# PCIE1_CORE_DBN_CFG_PCIE_CORE register map
Vendor: Texas Instruments
Registers are 32-bit, read-write, reset 0x0 unless marked. A register's access mark holds for its fields unless they carry their own. Offsets are as the file gives them; [hi:lo] are bit positions.

## PCIE1_CORE_DBN_CFG_PCIE_CORE (part 3 of 7)
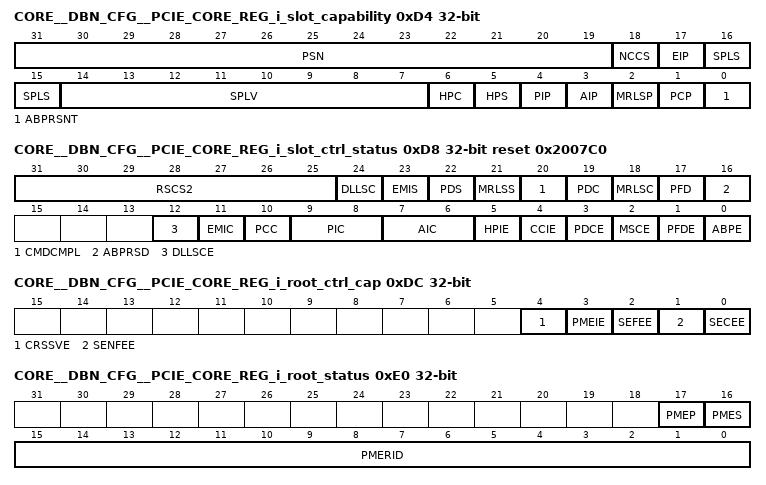
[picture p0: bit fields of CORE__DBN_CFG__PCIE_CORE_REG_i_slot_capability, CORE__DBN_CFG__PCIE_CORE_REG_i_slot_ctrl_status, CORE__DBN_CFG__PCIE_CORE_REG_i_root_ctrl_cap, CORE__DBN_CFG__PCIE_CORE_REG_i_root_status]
0xD4 CORE__DBN_CFG__PCIE_CORE_REG_i_slot_capability ro — The Slot Capabilities register identifies PCI Express slot specific capabilities.
  [31:19] PSN — This field indicates the physical slot number attached to this Port. This field must be hardware initialized to a value that assigns a slot number that is unique within the chassis, regardless of the form factor associated with the slot. This field must be initialized to zero for Ports connected to devices that are either integrated on the system board or integrated within the same silicon as the Switch device or Root Port.
  [18] NCCS — When Set, this bit indicates that this slot does not generate software notification when an issued command is completed by the Hot-Plug Controller. This bit is only permitted to be Set if the hot-plug capable Port is able to accept writes to all fields of the Slot Control register without delay between successive writes.
  [17] EIP — When Set, this bit indicates that an Electromechanical Interlock is implemented on the chassis for this slot.
  [16:15] SPLS — Specifies the scale used for the Slot Power Limit Value . Range of Values: 00b = 1.0x 01b = 0.1x 10b = 0.01x 11b = 0.001x This register must be implemented if the Slot Implemented bit is Set. Writes to this register also cause the Port to send the Set_Slot_Power_Limit Message. The default value prior to hardware/firmware initialization is 00b.
  [14:7] SPLV — In combination with the Slot Power Limit Scale value, specifies the upper limit on power supplied by the slot [see Section 6.9] or by other means to the adapter. Power limit [in Watts] is calculated by multiplying the value in this field by the value in the Slot Power Limit Scale field except when the Slot Power Limit Scale field equals 00b [1.0x] and Slot Power Limit Value exceeds EFh, the following alternative encodings are used: F0h = 250 W Slot Power Limit F1h = 275 W Slot Power Limit F2h = 300 W Slot Power Limit F3h to FFh = Reserved for Slot Power Limit values above 300 W This register must be implemented if the Slot Implemented bit is Set. Writes to this register also cause the Port to send the Set_Slot_Power_Limit Message. The default value prior to hardware/firmware initialization is 0000 0000b.
  [6] HPC — When Set, this bit indicates that this slot is capable of supporting hot-plug operations.
  [5] HPS — When Set, this bit indicates that an adapter present in this slot might be removed from the system without any prior notification. This is a form factor specific capability. This bit is an indication to the operating system to allow for such removal without impacting continued software operation.
  [4] PIP — When Set, this bit indicates that a Power Indicator is electrically controlled by the chassis for this slot.
  [3] AIP — When Set, this bit indicates that an Attention Indicator is electrically controlled by the chassis.
  [2] MRLSP — When Set, this bit indicates that an MRL Sensor is implemented on the chassis for this slot.
  [1] PCP — When Set, this bit indicates that a software programmable Power Controller is implemented for this slot/adapter [depending on form factor].
  [0] ABPRSNT — When Set, this bit indicates that an Attention Button for this slot is electrically controlled by the chassis.
0xD8 CORE__DBN_CFG__PCIE_CORE_REG_i_slot_ctrl_status access not given reset 0x2007C0 — This register contains control bits specific to PCI Express slot parameters and status bits specific to the PCI Express Slot. All the read-write bits in this register can also be written from the local management APB bus.
  [31:25] RSCS2 ro
  [24] DLLSC — This bit is Set when the value reported in the Data Link Layer Link Active bit of the Link Status register is changed. In response to a Data Link Layer State Changed event, software must read the Data Link Layer Link Active bit of the Link Status register to determine if the Link is active before initiating configuration cycles to the hot plugged device. (access R/W1TC)
  [23] EMIS ro — If an Electromechanical Interlock is implemented, this bit indicates the status of the Electromechanical Interlock. Defined encodings are: 0b Electromechanical Interlock Disengaged 1b Electromechanical Interlock Engaged
  [22] PDS ro — This bit indicates the presence of an adapter in the slot, reflected by the logical 'OR' of the Physical Layer in-band presence detect mechanism and, if present, any out-of-band presence detect mechanism defined for the slot's corresponding form factor. Note that the in-band presence detect mechanism requires that power be applied to an adapter for its presence to be detected. Consequently, form factors that require a power controller for hot-plug must implement a physical pin presence detect mechanism. Defined encodings are: 0b Slot Empty 1b Card Present in slot.
  [21] MRLSS ro — This bit reports the status of the MRL sensor if implemented. Defined encodings are: 0b MRL Closed 1b MRL Open
  [20] CMDCMPL — If Command Completed notification is supported [if the No Command Completed Support bit in the Slot Capabilities register is 0b], this bit is Set when a hot-plug command has completed and the Hot-Plug Controller is ready to accept a subsequent command. The Command Completed status bit is Set as an indication to host software that the Hot- Plug Controller has processed the previous command and is ready to receive the next command; it provides no guarantee that the action corresponding to the command is complete. If Command Completed notification is not supported, this bit must be hardwired to 0b. (access R/W1TC)
  [19] PDC — This bit is set when the value reported in the Presence Detect State bit is changed. (access R/W1TC)
  [18] MRLSC — If an MRL sensor is implemented, this bit is Set when a MRL Sensor state change is detected. If an MRL sensor is not implemented, this bit must not be Set. (access R/W1TC)
  [17] PFD — If a Power Controller that supports power fault detection is implemented, this bit is Set when the Power Controller detects a power fault at this slot. Note that, depending on hardware capability, it is possible that a power fault can be detected at any time, independent of the Power Controller Control setting or the occupancy of the slot. If power fault detection is not supported, this bit must not be Set. (access R/W1TC)
  [16] ABPRSD — If an Attention Button is implemented, this bit is Set when the attention button is pressed. If an Attention Button is not supported, this bit must not be Set. (access R/W1TC)
  [12] DLLSCE rw — If the Data Link Layer Link Active Reporting capability is 1b, this bit enables software notification when Data Link Layer Link Active bit is changed. If the Data Link Layer Link Active Reporting Capable bit is 0b, this bit is permitted to be read-only with a value of 0b. Default value of this bit is 0b.
  [11] EMIC ro — If an Electromechanical Interlock is implemented, a write of 1b to this bit causes the state of the interlock to toggle. A write of 0b to this bit has no effect. A read of this bit always returns a 0b.
  [10] PCC rw — If a Power Controller is implemented, this bit when written sets the power state of the slot per the defined encodings. Reads of this bit must reflect the value from the latest write, even if the corresponding hot-plug command is not complete, unless software issues a write, if required to, without waiting for the previous command to complete in which case the read value is undefined. The defined encodings are: 0b Power On 1b Power Off
  [9:8] PIC rw — If a Power Indicator is implemented, writes to this field set the Power Indicator to the written state. Reads of this field must reflect the value from the latest write,Defined encodings are: 00b Reserved 01b On 10b Blink 11b Off
  [7:6] AIC rw — If an Attention Indicator is implemented, writes to this field set the Attention Indicator to the written state. Reads of this field must reflect the value from the latest write,Defined encodings are: 00b Reserved 01b On 10b Blink 11b Off
  [5] HPIE rw — When Set, this bit enables generation of an interrupt on enabled hot-plug events. If the Hot Plug Capable bit in the Slot Capabilities register is Clear, this bit is permitted to be read-only with a value of 0b. Default value of this bit is 0b.
  [4] CCIE rw — If Command Completed notification is supported [if the No Command Completed Support bit in the Slot Capabilities register is 0b], when Set, this bit enables software notification when a hot-plug command is completed by the Hot-Plug Controller. If Command Completed notification is not supported, this bit must be hardwired to 0b. Default value of this bit is 0b.
  [3] PDCE rw — When Set, this bit enables software notification on a presence detect changed event. If the Hot-Plug Capable bit in the Slot Capabilities register is 0b, this bit is permitted to be read-only with a value of 0b. Default value of this bit is 0b.
  [2] MSCE rw — When Set, this bit enables software notification on a MRL sensor changed event If the MRL Sensor Present bit in the Slot Capabilities register is Clear, this bit is permitted to be read-only with a value of 0b. Default value of this bit is 0b.
  [1] PFDE rw — When Set, this bit enables software notification on a power fault event If a Power Controller that supports power fault detection is not implemented, this bit is permitted to be read-only with a value of 0b. Default value of this bit is 0b.
  [0] ABPE rw — When Set to 1b, this bit enables software notification on an attention button pressed event. If the Attention Button Present bit in the Slot Capabilities register is 0b, this bit is permitted to be read-only with a value of 0b. Default value of this bit is 0b.
0xDC CORE__DBN_CFG__PCIE_CORE_REG_i_root_ctrl_cap access per field — This register controls and identifies PCI Express Root Complex specific parameters.
  [4] CRSSVE ro — This capability is not implemented and this bit is hardwired to 0b.
  [3] PMEIE rw — This field can be read and written from the local management APB bus, but its value is not used within the Controller.
  [2] SEFEE rw — This field can be read and written from the local management APB bus, but its value is not used within the Controller.
  [1] SENFEE rw — This field can be read and written from the local management APB bus, but its value is not used within the Controller.
  [0] SECEE rw — This field can be read and written from the local management APB bus, but its value is not used within the Controller.
0xE0 CORE__DBN_CFG__PCIE_CORE_REG_i_root_status access not given — This register controls and identifies PCI Express Root Complex specific parameters.
  [17] PMEP ro — This field can be written from the APB bus by setting [21] bit high of the pcie_mgmt_APB_ADDR during a local management register write.
  [16] PMES — This field is not set by the Controller but can be cleared by writing a 1 from the local management APB bus. This field can be written from the APB bus by setting [21] bit high of the pcie_mgmt_APB_ADDR during a local management register write. (access R/W1TC)
  [15:0] PMERID ro — This field can be written from the APB bus by setting [21] bit high of the pcie_mgmt_APB_ADDR during a local management register write.
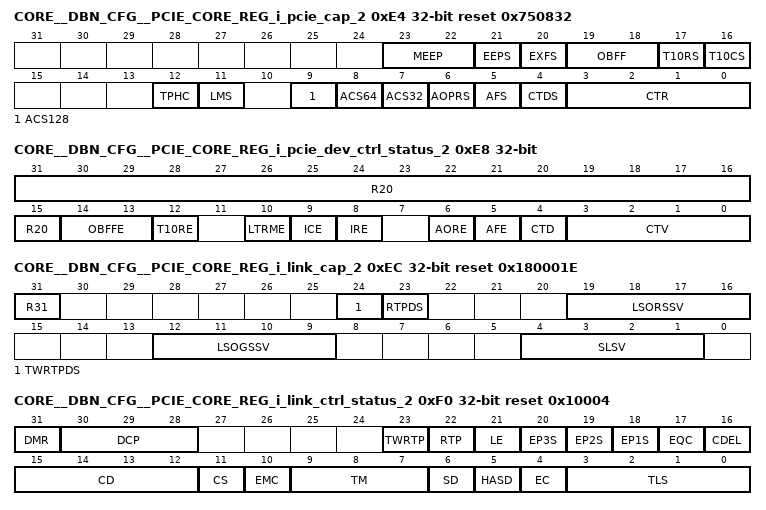
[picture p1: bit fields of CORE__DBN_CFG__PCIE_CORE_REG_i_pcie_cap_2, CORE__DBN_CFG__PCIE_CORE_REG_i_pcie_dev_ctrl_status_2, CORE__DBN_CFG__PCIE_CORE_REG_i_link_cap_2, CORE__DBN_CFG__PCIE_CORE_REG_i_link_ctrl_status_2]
0xE4 CORE__DBN_CFG__PCIE_CORE_REG_i_pcie_cap_2 ro reset 0x750832 — This register advertises the capabilities of the PCI Express device.
  [23:22] MEEP — Indicates the maximum number of End-End TLP Prefixes supported by the Function. The supported values are: 01b 1 End-End TLP Prefix 10b 2 End-End TLP Prefixes. This field can be written from the APB bus by setting [21] bit high of the pcie_mgmt_APB_ADDR during a local management register write
  [21] EEPS — Indicates whether the Function supports End-End TLP Prefixes. A 1 in this field indicates that the Function supports receiving TLPs containing End-End TLP Prefixes. This field can be written from the APB bus by setting [21] bit high of the pcie_mgmt_APB_ADDR during a local management register write
  [20] EXFS — Indicates that the Function supports the 3-bit definition of the Fmt field in the TLP header. This bit is hardwired to 1 for all Physical Functions.
  [19:18] OBFF — A 1 in this bit position indicates that the Function supports the Optimized Buffer Flush/Fill [OBFF] capability using message signaling. This field can be written from the APB bus by setting [21] bit high of the pcie_mgmt_APB_ADDR during a local management register write
  [17] T10RS — If set function supports 1-bit requester capability; otherwise, the function does not. This bit can be disabled using local management register.
  [16] T10CS — If set function supports 1-bit completer capability; otherwise, the function does not. This field can be modified using local management interface.
  [12] TPHC — Hardwired to 0.
  [11] LMS — A value of 1b indicates support for the optional Latency Tolerance Reporting [LTR] mechanism. This field can be written from the APB bus by setting [21] bit high of the pcie_mgmt_APB_ADDR during a local management register write.
  [9] ACS128 — Hardwired to 0.
  [8] ACS64 — Hardwired to 0.
  [7] ACS32 — Hardwired to 0.
  [6] AOPRS — Applicable only to Switch Upstream Ports, Switch Downstream Ports, and Root Ports; must be 0b for other Function types. This bit must be set to 1b if the Port supports this optional capability. This field can be written from the APB bus by setting [21] bit high of the pcie_mgmt_APB_ADDR during a local management register write.
  [5] AFS — A 1 in this bit indicates that the device is able to forward TLPs with function number greater than 8. This field can be written from the APB bus by setting [21] bit high of the pcie_mgmt_APB_ADDR during a local management register write.
  [4] CTDS — A 1 in this field indicates that the associated Function supports the capability to turn off its Completion timeout. This field can be written from the APB bus by setting [21] bit high of the pcie_mgmt_APB_ADDR during a local management register write.
  [3:0] CTR — Specifies the Completion Timeout values supported by the device. This field is set by default to 0010 [10 ms - 250 ms], but can be modified from the local management APB bus. The actual timeout values are in two programmable local management registers, which allow the timeout settings of the two sub-ranges within Range B to be programmed independently. This field can be written from the APB bus by setting [21] bit high of the pcie_mgmt_APB_ADDR during a local management register write.
0xE8 CORE__DBN_CFG__PCIE_CORE_REG_i_pcie_dev_ctrl_status_2 access per field — This register contains control and status bits associated with the device.
  [31:15] R20 ro
  [14:13] OBFFE rw — Enables the Optimized Buffer Flush/Fill [OBFF] capability in the device. Valid settings are 00 [disabled], 01 [Variation A], and 10 [Variation B].
  [12] T10RE ro — 10bit TAGs generation are not supported in this configuration.
  [10] LTRME rw — This must be set to 1 to enable the Latency Tolerance Reporting Mechanism. This bit is implemented only in PF 0. Its default value is 1, but can be modified from the local management bus. This bit is read-only in PF 1.
  [9] ICE rw — When this bit is 1, the RC is allowed to set the ID-based Ordering [IDO] Attribute bit in the Completions it generates.
  [8] IRE rw — When this bit is 1, the RC is allowed to set the ID-based Ordering [IDO] Attribute bit in the requests it generates.
  [6] AORE ro — This bit must be set to enable the generation of Atomic Op Requests. If the client logic attempts to send an Atomic Op when this bit is not set, logic in the Controller will nullify the TLP on its way to the link.
  [5] AFE rw — A 1 in this filed indicates that the port treats fields 7:0 of the ID as function number while converting a Type 1 config packet to type 0 config packet.
  [4] CTD rw — Setting this bit disables the Completion Timeout in the device.
  [3:0] CTV rw — Specifies the Completion Timeout value for the device. Allowable values are 0101 [sub-range 1] and 0110 [sub-range 2]. The corresponding timeout values are stored in the local management register's Completion Timeout Interval Registers 0 and 1, respectively. Value of 0 selects completion timeout from Completion-Timeout-Interval-Registers-0 in local management register.
0xEC CORE__DBN_CFG__PCIE_CORE_REG_i_link_cap_2 ro reset 0x180001E — This register advertises the supported link speeds of the Controller.
  [31] R31 — Indicates support for the optional Device Readiness Status [DRS] capability. This capability is currently not supported in the Controller.
  [24] TWRTPDS — When set to 1b, this bit indicates that the associated Port supports detection and reporting of two Retimers presence. This bit is valid for both Downstream Ports and Upstream Ports.
  [23] RTPDS — When set to 1b, this bit indicates that the associated Port supports detection and reporting of Retimer presence. This bit is valid for both Downstream Ports and Upstream Ports.
  [19:16] LSORSSV — If this field is non-zero, it indicates that the Port, when operating at the indicated speed[s] supports SRIS and also supports receiving SKP OS at the rate defined for SRNS while running in SRIS.
  [12:9] LSOGSSV — If this field is non-zero, it indicates that the Port, when operating at the indicated speed[s] supports SRIS and also supports software control of the SKP Ordered Set transmission scheduling rate.
  [4:1] SLSV — This field indicates the supported link speeds of the Controller. For each bit, a value of 1 indicates that the corresponding link speed is supported, while a value of 0 indicates that the corresponding speed is not supported. The bits corresponding to various link speeds are: Bit 1 = Link Speed 2.5 GT/s, Bit 2 = Link Speed 5 GT/s, Bit 3 = Link Speed 8 GT/s, Bit 4 = Link Speed 16 GT/s. This field is hardwired to 0001 [2.5 GT/s] when the PCIE_GENERATION_SEL strap pins of the Controller are set to 0, 0011 [2.5 and 5 GT/s] when the strap is set to 1, and 0111 [2.5, 5, and 8 GT/s] when the strap pin is set to 10, and 1111 [2.5, 5, 8 and 16 GT/s] when the strap pin is set to 11.
0xF0 CORE__DBN_CFG__PCIE_CORE_REG_i_link_ctrl_status_2 access not given reset 0x10004 — This register contains control and status bits specific to the PCI Express link.
  [31] DMR ro — DRS is not supported by the Controller and hence this field is not implemented.
  [30:28] DCP ro — DRS is not supported by the Controller and hence this field is not implemented.
  [23] TWRTP ro — When set to 1b, this bit indicates that two Retimers were present during the most recent Link negotiation.
  [22] RTP ro — When set to 1b, this bit indicates that a Retimer was present during the most recent Link negotiation.
  [21] LE — When the Controller [RP] receives an 8GTs equalization request from an Upstream Port the Controller internally sets this bit to 1. [i.e. when RP is in the Recovery.RcvrCfg state and receives 8 consecutive TS2 Ordered Sets with the Request Equalization bit set to 1b] The LOCAL_INTERRUPT output is also asserted if Link Equalization Request Interrupt Enable is enabled. (access R/W1TC)
  [20] EP3S ro — This bit, when set to 1, indicates that the Phase 3 of the Transmitter Equalization procedure has completed successfully. STICKY
  [19] EP2S ro — This bit, when set to 1, indicates that the Phase 2 of the Transmitter Equalization procedure has completed successfully. STICKY
  [18] EP1S ro — This bit, when set to 1, indicates that the Phase 1 of the Transmitter Equalization procedure has completed successfully. STICKY
  [17] EQC ro — This bit, when set to 1, indicates that the Transmitter Equalization procedure has completed. STICKY
  [16] CDEL ro — This status bit indicates the current operating de-emphasis level of the transmitter [0 = -6dB, 1 = -3.5dB].
  [15:12] CD rw — This bit sets the de-emphasis level [for 5 GT/s operation] or the Transmitter Preset level [for 8 GT/s or 16 GT/s operation] when the LTSSM enters the Polling.Compliance state because of software setting the Enter Compliance bit in this register. It is used only when the link is running at 5 GT/s or 8 GT/s or 16 GT/s. At 5 GT/s, the only valid setting are 0 [-6 dB] and 1 [-3.5 dB]. STICKY
  [11] CS rw — When this bit is set to 1, the device will transmit SKP ordered sets between compliance patterns. STICKY
  [10] EMC rw — This field is intended for debug and compliance testing purposes only. If this bit is set to 1, the device will transmit the Modified Compliance Pattern when the LTSSM enters the Polling.Compliance substate. STICKY
  [9:7] TM rw — This field is intended for debug and compliance testing purposes only. It controls the non-deemphasized voltage level at the transmitter outputs. Its encodings are: 000 = Normal operating range, 001 = 800 - 1200 mV for full swing and 400 - 700 mV for half swing, 010 - 111 = See PCI Express Base Specification 2.0. This field is reset to 0 when th LTSSM enters the Polling.Configuration substate during link training. STICKY.
  [6] SD rw — This bit selects the de-emphasis level when the Controller is operating at 5 GT/s [0 = -6 dB, 1 = -3.5 dB].
  [5] HASD rw — When this bit is set, the LTSSM is prevented from changing the operating speed of the link, other than reducing the speed to correct unreliable operation of the link. STICKY
  [4] EC rw — This bit is used to force the Endpoint device to enter the Compliance mode. Software sets this bit to 1 and initiates a hot reset to force the device into the Compliance mode. The target speed for the Compliance mode is determined by the Target Link Speed field of this register. STICKY.
  [3:0] TLS rw — This field sets the target speed when the software forces the link into Compliance mode by setting the Enter Compliance bit in this register [0001 = 2.5 GT/s, 0010 = 5 GT/s, 0100 = 8 GT/s,1000 = 16 GT/s]. The default value of this field is 0001 [2.5 GT/s] when the PCIE_GENERATION_SEL[1:0] strap pins of the Controller are set to 0, 0010 [5 GT/s] when the strap is set to 1, and 0011 [8 GT/s] when the strap pin is set to 10 , and 0100 [16 GT/s] when the strap pin is set to 11. STICKY.
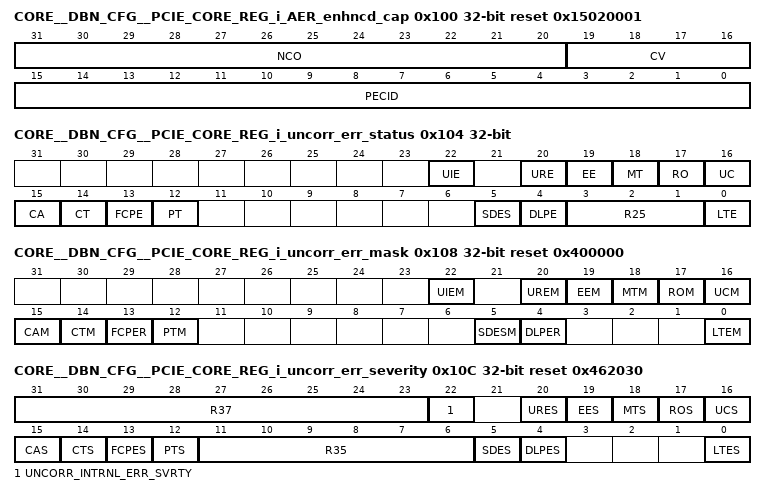
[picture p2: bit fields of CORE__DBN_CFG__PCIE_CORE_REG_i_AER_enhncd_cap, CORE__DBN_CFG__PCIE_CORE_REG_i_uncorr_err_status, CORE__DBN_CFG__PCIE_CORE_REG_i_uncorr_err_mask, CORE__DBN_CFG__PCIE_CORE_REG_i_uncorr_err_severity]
0x100 CORE__DBN_CFG__PCIE_CORE_REG_i_AER_enhncd_cap ro reset 0x15020001 — This is the first register in the PCI Express Advanced Error Reporting Capability Structure. This register contains the PCI Express Extended Capability ID, the capability version , and the pointer to the next capability structure.
  [31:20] NCO — Indicates offset to the next PCI Express capability structure. The default next pointer value is dynamic and is dependent on whether the strap or LMI bits are set.
  [19:16] CV — Specifies the SIG assigned value for the version of the capability structure. This field is set by default to 4'h2.
  [15:0] PECID — This field is hardwired to the Capability ID assigned by PCI SIG to the PCI Express AER Extended Capability Structure [0001 hex].
0x104 CORE__DBN_CFG__PCIE_CORE_REG_i_uncorr_err_status access not given — This register provides the status of the various uncorrectable errors detected by the PCI Express Controller. Software may clear any error bit by writing a 1 into the corresponding bit position. The states of the bits in the Uncorrectable Error Mask Register have no effect on the status bits of this register. In the case of certain errors detected by the Transaction Layer, the associated TLP header is logged in the Header Log Registers.
  [22] UIE — This bit is set when the Controller has detected an internal uncorrectable error [HAL parity error or an uncorrectable ECC error while reading from any of the RAMs]. This bit is also set in response to the client signaling an internal error through the input UNCORRECTABLE_ERROR_IN. This error is considered fatal by default. (access R/W1TC)
  [20] URE — This bit is set when the Controller has received a request from the link that it does not support. This error is not Function-specific. This error is considered non-fatal by default, except for the special case outlined in PCI Express Base Specification 2.0. The header of the received request that caused the error is logged in the Header Log Registers. (access R/W1TC)
  [19] EE — This bit is set when the Controller has detected an ECRC error in a received TLP. (access R/W1TC)
  [18] MT — This bit is set when the Controller receives a malformed TLP from the link. This error is considered fatal by default. The header of the received TLP with error is logged in the Header Log Registers. (access R/W1TC)
  [17] RO — This bit is set when the Controller receives a TLP in violation of the receive credit currently available. (access R/W1TC)
  [16] UC — This bit is set when the Controller has received an unexpected Completion packet from the link. (access R/W1TC)
  [15] CA — This bit is set when the Controller has returned the Completer Abort [CA] status to a request received from the link. This error is considered non-fatal by default, except for the special cases outlined in PCI Express Base Specification 2.0. The header of the received request that caused the error is logged in the Header Log Registers. (access R/W1TC)
  [14] CT — This bit is set when the completion timer associated with an outstanding request times out. This error is considered non-fatal by default. (access R/W1TC)
  [13] FCPE — This bit is set when certain violations of the flow control protocol are detected by the Controller. (access R/W1TC)
  [12] PT — This bit is set when the Controller receives a poisoned TLP from the link. This error is considered non-fatal by default. The header of the received TLP with error is logged in the Header Log Registers. (access R/W1TC)
  [5] SDES — This error status indicates Link up to Link down event. So Status bit is set upon LINK_DOWN_RESET_OUT event. This field is applicable to RC only and not for EP as per PCIE-spec. (access R/W1TC)
  [4] DLPE — This bit is set when the Controller receives an Ack or Nak DLLP whose sequence does not correspond to that of an unacknowledged TLP or that of the last acknowledged TLP [for details, refer to the PCI Express Base Specifications]. (access R/W1TC)
  [3:1] R25 ro
  [0] LTE — This error indicates that link training is not successful and transition back to detect state. This Status bit is set on any LTSSM transition from Configuration to Detect or Recovery to Detect. This field is applicable to RC only and not for EP as per PCIE-spec. (access R/W1TC)
0x108 CORE__DBN_CFG__PCIE_CORE_REG_i_uncorr_err_mask reset 0x400000 — The mask bits in this register control the reporting of uncorrectable errors. For each error type in the Uncorrectable Error Status Register, there is a corresponding bit in this register to mask its reporting. Setting the mask bit has the following effects: (1) The occurrence of the error does not cause activation of the FATAL_ERROR_OUT or NON_FATAL_ERROR_OUT output of the Controller, depending on the severity of the error. (2) The header of the TLP in which the error was detected is not logged in the Header Log Registers. (3) The First Error Pointer in the Advanced Error Capabilities and Control Register is not updated on the detection of the error. The individual bits of the mask register are described below.
  [22] UIEM — This bit is set to mask the reporting of internal errors. STICKY.
  [20] UREM — This bit is set to mask the reporting of unexpected requests received from the link. STICKY.
  [19] EEM — This bit is set to mask the reporting of ECRC errors. STICKY.
  [18] MTM — This bit is set to mask the reporting of malformed TLPs received from the link. STICKY.
  [17] ROM — This bit is set to mask the reporting of violations of receive credit. STICKY.
  [16] UCM — This bit is set to mask the reporting of unexpected Completions received by the Controller. STICKY.
  [15] CAM — This bit is set to mask the reporting of the Controller sending a Completer Abort. STICKY.
  [14] CTM — This bit is set to mask the reporting of Completion Timeouts. STICKY.
  [13] FCPER — This bit is set to mask the reporting of Flow Control Protocol Errors. STICKY.
  [12] PTM — This bit is set to mask the reporting of a Poisoned TLP. STICKY.
  [5] SDESM — This bit is set to mask the reporting of Surprise Down Error Status Mask. STICKY. This field is applicable to RC only and not for EP as per PCIE-spec.
  [4] DLPER — This bit is set to mask the reporting of Data Link Protocol Errors. STICKY.
  [0] LTEM — This bit is set to mask the reporting of Link Training Error Mask. STICKY. This field is applicable to RC only and not for EP as per PCIE-spec.
0x10C CORE__DBN_CFG__PCIE_CORE_REG_i_uncorr_err_severity access per field reset 0x462030 — The setting of this register determines whether an uncorrectable error is reported as a fatal error or non-fatal, that is, whether the FATAL_ERROR_OUT or NON_FATAL_ERROR_OUT output of the Controller is activated. If a severity bit of this register is 0,the corresponding error is reported by the Controller by asserting NON_FATAL_ERROR_OUT. Otherwise, it is reported by asserting FATAL_ERROR_OUT.
  [31:23] R37 ro
  [22] UNCORR_INTRNL_ERR_SVRTY rw — Severity of internal errors [0 = Non-Fatal, 1 = Fatal].
  [20] URES rw — Severity of unexpected requests received from the link [0 = Non-Fatal, 1 = Fatal]. STICKY.
  [19] EES rw — Severity of ECRC errors [0 = Non-Fatal, 1 = Fatal]. STICKY.
  [18] MTS rw — Severity of malformed TLPs received from the link [0 = Non-Fatal, 1 = Fatal]. STICKY.
  [17] ROS rw — Severity of receive credit violations [0 = Non-Fatal, 1 = Fatal]. STICKY.
  [16] UCS rw — Severity of unexpected Completions received by the Controller [0 = Non-Fatal, 1 = Fatal]. STICKY.
  [15] CAS rw — Severity of sending a Completer Abort [0 = Non-Fatal, 1 = Fatal]. STICKY.
  [14] CTS rw — Severity of Completion Timeouts [0 = Non-Fatal, 1 = Fatal]. STICKY.
  [13] FCPES rw — Severity of a Flow Control Protocol Error [0 = Non-Fatal, 1 = Fatal]. STICKY.
  [12] PTS rw — Severity of a Poisoned TLP error [0 = Non-Fatal, 1 = Fatal]. STICKY.
  [11:6] R35 ro
  [5] SDES rw — surprise down error severity [0 = Non-Fatal, 1 = Fatal]. STICKY. This field is applicable to RC only and not for EP as per PCIE-spec.
  [4] DLPES rw — Severity of Data Link Protocol Errors [0 = Non-Fatal, 1 = Fatal]. STICKY.
  [0] LTES rw — Severity of Link Training Error [0 = Non-Fatal, 1 = Fatal]. STICKY. This field is applicable to RC only and not for EP as per PCIE-spec.
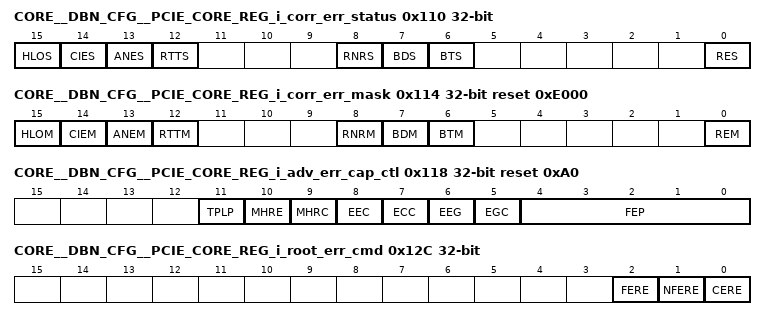
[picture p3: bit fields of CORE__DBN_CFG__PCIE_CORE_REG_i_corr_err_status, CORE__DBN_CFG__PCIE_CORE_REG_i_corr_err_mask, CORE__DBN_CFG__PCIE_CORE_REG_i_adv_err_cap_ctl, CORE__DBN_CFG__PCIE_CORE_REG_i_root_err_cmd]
0x110 CORE__DBN_CFG__PCIE_CORE_REG_i_corr_err_status access not given — This register provides the status of the various correctable errors detected by the PCI Express Controller. Software may clear any error bit by writing a 1 into the corresponding bit position. The states of the bits in the Correctable Error Mask Register have no effect on the status bits of this register. The setting of a correctable error status bit causes the Controller to assert the CORRECTABLE_ERROR_OUT output if the error is not masked in the Correctable Error Mask Register. Header logging of received TLPs does not apply to correctable errors.
  [15] HLOS — This bit is set on a Header Log Register overflow, that is, when the header could not be logged in the Header Log Register because it is occupied by a previous header. (access R/W1TC)
  [14] CIES — This bit is set when the Controller has detected an internal correctable error condition [a correctable ECC error while reading from any of the RAMs]. This bit is also set in response to the client signaling an internal error through the input CORRECTABLE_ERROR_IN. (access R/W1TC)
  [13] ANES — This bit is set when an uncorrectable error occurs, which is determined to belong to one of the special cases described in the PCI Express Base Specification 2.0. This causes the Controller to assert the CORRECTABLE_ERROR_OUT output in place of NON_FATAL_ERROR_OUT. (access R/W1TC)
  [12] RTTS — This bit is set when the replay timer in the Data Link Layer of the Controller times out, causing the Controller to re-transmit a TLP. (access R/W1TC)
  [8] RNRS — This bit is set when the replay count rolls over after three re-transmissions of a TLP at the Data Link Layer of the Controller. (access R/W1TC)
  [7] BDS — This bit is set when an LCRC error is detected in a received DLLP, and no errors were detected by the Physical Layer. (access R/W1TC)
  [6] BTS — This bit is set when an error is detected in a received TLP by the Data Link Layer of the Controller the conditions causing this error are [1] an LCRC error, [2] the packet terminates with EDB symbol, but its LCRC field does not equal the inverted value of the calculated CRC. (access R/W1TC)
  [0] RES — This bit is set when an error is detected in the receive side of the Physical Layer of the Controller [e.g. an 8b10b decode error]. (access R/W1TC)
0x114 CORE__DBN_CFG__PCIE_CORE_REG_i_corr_err_mask reset 0xE000 — The mask bits in this register control the reporting of correctable errors. For each error type in the Correctable Error Status Register, there is a corresponding bit in this register to mask its reporting. When a mask bit is set the occurrence of the error is not reported (by asserting the CORRECTABLE_ERROR_OUT output).
  [15] HLOM — This bit, when set, masks the reporting of an error in response to a Header Log register overflow. STICKY.
  [14] CIEM — This bit, when set, masks the reporting of an error in response to a corrected internal error condition. STICKY.
  [13] ANEM — This bit, when set, masks the reporting of an error in response to an uncorrectable error occurence, which is determined to belong to one of the special cases in the PCI Express Base Specification 2.0. STICKY.
  [12] RTTM — This bit, when set, masks the reporting of an error in response to a Replay Timer timeout event. STICKY.
  [8] RNRM — This bit, when set, masks the reporting of an error in response to a Replay Number Rollover event. STICKY.
  [7] BDM — This bit, when set, masks the reporting of an error in response to a 'Bad DLLP' received. STICKY.
  [6] BTM — This bit,when set, masks the reporting of an error in response to a 'Bad TLP' received. STICKY.
  [0] REM — This bit, when set, masks the reporting of Physical Layer errors. STICKY.
0x118 CORE__DBN_CFG__PCIE_CORE_REG_i_adv_err_cap_ctl access per field reset 0xA0 — This register contains a pointer to the first error that is reported in the Uncorrectable Error Status Register, and bits to enable ECRC generation and checking.
  [11] TPLP ro — If Set and the First Error Pointer is valid, indicates that the TLP Prefix Log register contains valid information. If Clear or if First Error Pointer is invalid, the TLP Prefix Log register is undefined. Default value of this bit is 0. This bit is RsvdP if the End-End TLP Prefix Supported bit is CIf Set and the First Error Pointer is valid, indicates that the TLP Prefix Log register contains valid information. If Clear or if First Error Pointer is invalid, the TLP Prefix Log register is undefined.
  [10] MHRE ro — Setting this bit enables the RC to log multiple error headers in its Header Log Registers. It is hardwired to 0.
  [9] MHRC ro — This bit is set when the RC has the capability to log more than one error header in its Header Log Registers. It is hardwired to 0.
  [8] EEC rw — Setting this bit enables ECRC checking on the receive side of the Controller. This bit is writable from the local management bus. STICKY.
  [7] ECC ro — This read-only bit indicates to the software that the device is capable of checking ECRC in packets received from the link.
  [6] EEG rw — Setting this bit enables the ECRC generation on the transmit side of the Controller. This bit is writable from the local management bus. STICKY.
  [5] EGC ro — This read-only bit indicates to the software that the device is capable of generating ECRC in packets transmitted on the link.
  [4:0] FEP ro — This is a 5-bit pointer to the bit position in the Uncorrectable Error Status Register corresponding to the error that was detected first. When there are multiple bits set in the Uncorrectable Error Status Register, this field informs the software which error was observed first. To prevent the field from being overwritten before the software is able to read it, this field is not updated while the status bit it points to in the Uncorrectable Error Status Register remains set. After the software clears this status bit, a subsequent error condition that sets any bit in the Uncorrectable Error Status Register will update the First Error Pointer. Any uncorrectable error type, including the special cases where the error is reported using an ERR_COR message, will set the First Error Pointer [assuming the software has reset the error pointed by it in the Uncorrectable Error Status Register]. STICKY.
0x11C CORE__DBN_CFG__PCIE_CORE_REG_i_hdr_log_0 ro — This is the first of a set of four registers used to capture the header of a TLP received by the Controller from the link upon detection of an uncorrectable error. When multiple bits are set in the Uncorrectable Error Status Register, the captured header corresponds the the error that was detected first, that is, the error pointed by the First Error Pointer. To prevent the captured header from being over-written before software is able to read it, this register is not updated while the status bit pointed to by the First Error Pointer in the Uncorrectable Error Status Register remains set. After the software clears this status bit, a subsequent error condition that sets any bit in the Uncorrectable Error Status Register will also cause the Header Log Registers to be updated. The doublewords of the TLP header are stored in the Header Log Registers with their bytes transposed. That is, the byte containing the Type/Format fields of the header is stored at bit positions 31:24 of the Header Log Register 0.
  [31:0] HD0 — First Dword of captured TLP header. STICKY.
0x120 CORE__DBN_CFG__PCIE_CORE_REG_i_hdr_log_1 ro — This register contains the second Dword of the captured TLP header. The bytes are stored in transposed order.
  [31:0] HD1 — Second Dword of captured TLP header. STICKY.
0x124 CORE__DBN_CFG__PCIE_CORE_REG_i_hdr_log_2 ro — This register contains the third Dword of the captured TLP header. The bytes are stored in transposed order.
  [31:0] HD2 — Third Dword of captured TLP header. STICKY.
0x128 CORE__DBN_CFG__PCIE_CORE_REG_i_hdr_log_3 ro — If the captured TLP header is 4 Dwords long, this register contains its fourth Dword. If the captured header is a 3-Dword header, this register is unused. The bytes of the Dword are stored in this register in transposed order.
  [31:0] HD3 — Fourth Dword of captured TLP header. STICKY.
0x12C CORE__DBN_CFG__PCIE_CORE_REG_i_root_err_cmd — This register contains bits that control how the RC responds to errors reported by remote devices.
  [2] FERE — If this bit is set, the Controller will active its FATAL_ERROR_OUT output in response to an error message received from the link.
  [1] NFERE — If this bit is set, the Controller will active its NON_FATAL_ERROR_OUT output in response to an error message received from the link.
  [0] CERE — If this bit is set, the Controller will active its CORRECTABLE_ERROR_OUT output in response to an error message received from the link.
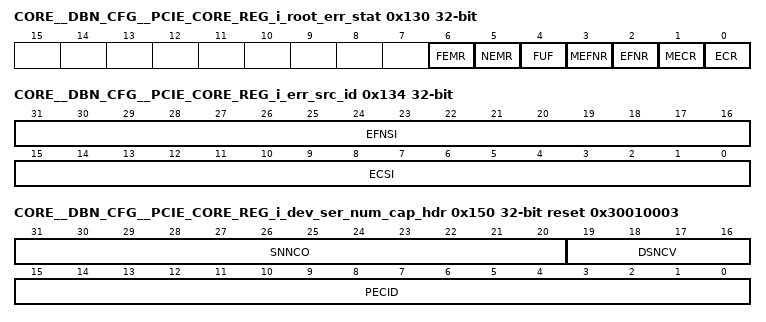
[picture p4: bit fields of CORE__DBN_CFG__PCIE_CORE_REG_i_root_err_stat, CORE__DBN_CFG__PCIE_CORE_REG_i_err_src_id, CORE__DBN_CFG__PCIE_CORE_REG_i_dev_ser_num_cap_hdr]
0x130 CORE__DBN_CFG__PCIE_CORE_REG_i_root_err_stat access not given — This register contains status information on error messages received from the link (that is, errors reported by remote devices attached to this Root Complex).
  [6] FEMR — This bit, when set, indicates that the RC has received one or more Fatal error messages from the link. STICKY (access R/W1TC)
  [5] NEMR — This bit, when set, indicates that the RC has received one or more Non-Fatal error messages from the link. STICKY (access R/W1TC)
  [4] FUF — This bit, when set, indicates that the first Uncorrectable error message received was for a Fatal error. STICKY (access R/W1TC)
  [3] MEFNR — This bit is set when the RC receives either a Fatal or Non-Fatal error message from the link, and the ERR_FATAL/NONFATAL Received bit is already set. STICKY (access R/W1TC)
  [2] EFNR — This bit is set when the RC receives either a Fatal or Non-Fatal error message from the link. STICKY (access R/W1TC)
  [1] MECR — This bit is set when the RC receives a Correctable error message from the link, if the ERR_COR received bit is already set. STICKY (access R/W1TC)
  [0] ECR — This bit is set when the RC receives a Correctable error message from the link. STICKY (access R/W1TC)
0x134 CORE__DBN_CFG__PCIE_CORE_REG_i_err_src_id ro — This register stores the Register IDs extracted from error messages received by the Root Complex from the link.
  [31:16] EFNSI — This field captures and stores the Requester ID from an ERR_FATAL or ERROR_NONFATAL message received by the RC, if the ERR_FATAL or NONFATAL Received bit was not set at the time the message was received. STICKY
  [15:0] ECSI — This field captures and stores the Requester ID from an ERR_COR message received by the RC, if the ERR_COR bit was not set at the time the message was received. STICKY
0x138 CORE__DBN_CFG__PCIE_CORE_REG_i_tlp_pre_log_0 ro — First TLP Prefix (if present) associated with the TLP whose header is in the Header Log Register. The bytes are in transposed order.
  [31:0] HD1 — First TLP Prefix of captured TLP STICKY.
0x150 CORE__DBN_CFG__PCIE_CORE_REG_i_dev_ser_num_cap_hdr ro reset 0x30010003 — This register contains the PCI Express Extended Capability ID for Device Serial Number Capability, the capability version, and the pointer to the next capability structure.
  [31:20] SNNCO — Indicates offset to the next PCI Express capability structure. The default next pointer value is dynamic and is dependent on whether the strap or LMI bits are set.
  [19:16] DSNCV — Specifies the SIG assigned value for the version of the capability structure. This field is set by default to 1, but can be modified from the local management bus by writing into Function 0 from the local management bus.
  [15:0] PECID — This field is hardwired to the Capability ID assigned by PCI SIG to the PCI Express Device Serial Number Capability [0001 hex].
0x154 CORE__DBN_CFG__PCIE_CORE_REG_i_dev_ser_num_0 ro — This read-only register stored the first 32 bits of the device's serial number.
  [31:0] DSND0 — This field contains the first 32 bits of the device's serial number. This field can be written from the APB bus by setting [21] bit high of the pcie_mgmt_APB_ADDR during a local management register write.
0x158 CORE__DBN_CFG__PCIE_CORE_REG_i_dev_ser_num_1 ro — This read-only register stored the last 32 bits of the device's serial number.
  [31:0] DSND1 — This field contains the last 32 bits of the device's serial number. This field can be written from the APB bus by setting [21] bit high of the pcie_mgmt_APB_ADDR during a local management register write.
